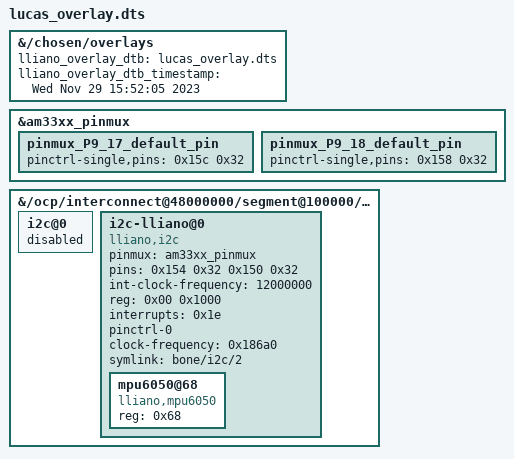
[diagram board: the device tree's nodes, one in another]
/dts-v1/;   // Version
/plugin/;   // Needed to indicate that this is an OVERLAY, and not a raw device tree.

&{/chosen/overlays} {
    lliano_overlay_dtb = "lucas_overlay.dts";
    lliano_overlay_dtb_timestamp = "Wed Nov  29 15:52:05 2023";
};


// I2C1 pins as I2C by default
&am33xx_pinmux {
    pinmux_P9_17_default_pin {
        pinctrl-single,pins = <0x15c 0x32>;
    };

    pinmux_P9_18_default_pin {
        pinctrl-single,pins = <0x158 0x32>;
    };
};

&{/ocp/interconnect@48000000/segment@100000/target-module@9c000} {
    
    // Repetimos estas dos configuraciones para ahorrarnos problemas 
    // en el reg cuando compilamos.
    #address-cells = <0x01>;
    #size-cells = <0x01>;

    i2c@0 {
        status = "disabled";    // Deshabilito el i2c2 por default.
    };

    // Me creo mi propio i2c
    i2c-lliano@0 {
        // Valores importantes
        #address-cells = <0x01>;    // Cuantas address tiene el reg de los hijos
        #size-cells = <0x00>;       // Cuantos sizes tiene el reg de los hijos
        compatible = "lliano,i2c";
        status = "okay";
        
        pinmux = <&am33xx_pinmux>;          // phandle to pin mux
        pins = <0x154 0x32 0x150 0x32>;     // <PIN_OFFSET PIN_MODE>
        int-clock-frequency = <12000000>;   // internal clock frequency 12MHz

        reg = <0x00 0x1000>;
        interrupts = <0x1e>;
        pinctrl-names = "default";
        pinctrl-0;
        clock-frequency = <0x186a0>;        // f = 400kHz
        symlink = "bone/i2c/2";

        

        // Dispositivos dentro del bus
        mpu6050@68 {
            compatible = "lliano,mpu6050";
            reg = <0x68>;
            status = "okay";
        };
    };
};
